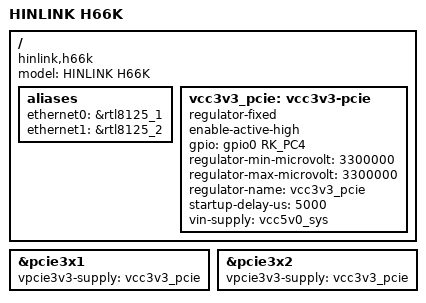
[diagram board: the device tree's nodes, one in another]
// SPDX-License-Identifier: (GPL-2.0+ OR MIT)
/*
 * Copyright (c) 2020 Rockchip Electronics Co., Ltd.
 *
 */

/dts-v1/;

#include "rk3568-h6xk.dtsi"

/ {
	model = "HINLINK H66K";
	compatible = "hinlink,h66k", "rockchip,rk3568";

	aliases {
		ethernet0 = &rtl8125_1;
		ethernet1 = &rtl8125_2;
	};

	vcc3v3_pcie: vcc3v3-pcie {
		compatible = "regulator-fixed";
		enable-active-high;
		gpio = <&gpio0 RK_PC4 GPIO_ACTIVE_HIGH>;
		regulator-min-microvolt = <3300000>;
		regulator-max-microvolt = <3300000>;
		regulator-name = "vcc3v3_pcie";
		startup-delay-us = <5000>;
		vin-supply = <&vcc5v0_sys>;
	};
};

&pcie3x1 {
	vpcie3v3-supply = <&vcc3v3_pcie>;
};

&pcie3x2 {
	vpcie3v3-supply = <&vcc3v3_pcie>;
};
